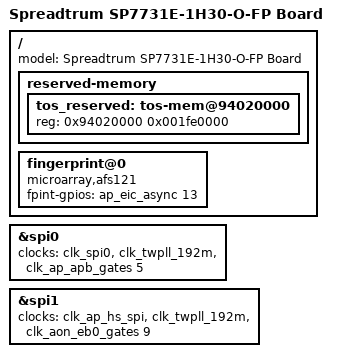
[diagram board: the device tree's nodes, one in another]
/*
 * Spreadtrum SP7731E 1H30-O WITH FINGERPRINT board DTS file
 *
 * Copyright (C) 2016-2017, Spreadtrum Communications Inc.
 *
 * This file is licensed under a dual GPLv2 or X11 license.
 */
#include "sp7731e-1h30-o-native.dts"

/ {
	model = "Spreadtrum SP7731E-1H30-O-FP Board";
	reserved-memory {
		tos_reserved: tos-mem@94020000{
			reg = <0x94020000 0x001fe0000>;
		};
	};

	fingerprint@0 {
		compatible = "microarray,afs121";
		fpint-gpios = <&ap_eic_async 13 0>;
	};
};

&spi0 {
		clocks = <&clk_spi0>, <&clk_twpll_192m>,
				<&clk_ap_apb_gates 5>;
};

&spi1 {
		clocks = <&clk_ap_hs_spi>, <&clk_twpll_192m>,
				<&clk_aon_eb0_gates 9>;
		status = "okay";
};
